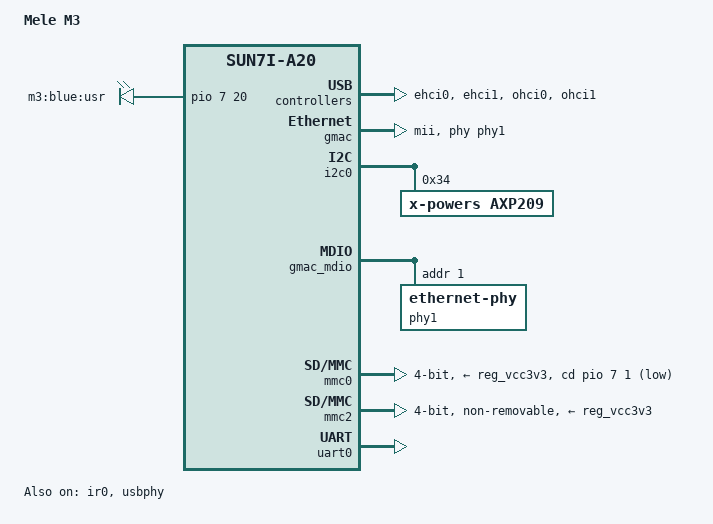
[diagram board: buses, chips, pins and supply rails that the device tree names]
/dts-v1/;
#include "sun7i-a20.dtsi"
#include "sunxi-common-regulators.dtsi"
#include <dt-bindings/gpio/gpio.h>
#include <dt-bindings/interrupt-controller/irq.h>
/ {
	model = "Mele M3";
	compatible = "mele,m3", "allwinner,sun7i-a20";
	aliases {
		serial0 = &uart0;
	};
	chosen {
		stdout-path = "serial0:115200n8";
	};
	leds {
		compatible = "gpio-leds";
		led {
			label = "m3:blue:usr";
			gpios = <&pio 7 20 GPIO_ACTIVE_HIGH>;
		};
	};
};
&ehci0 {
	status = "okay";
};
&ehci1 {
	status = "okay";
};
&gmac {
	pinctrl-names = "default";
	pinctrl-0 = <&gmac_mii_pins>;
	phy-handle = <&phy1>;
	phy-mode = "mii";
	status = "okay";
};
&i2c0 {
	status = "okay";
	axp209: pmic@34 {
		compatible = "x-powers,axp209";
		reg = <0x34>;
		interrupt-parent = <&nmi_intc>;
		interrupts = <0 IRQ_TYPE_LEVEL_LOW>;
		interrupt-controller;
		#interrupt-cells = <1>;
	};
};
&ir0 {
	pinctrl-names = "default";
	pinctrl-0 = <&ir0_rx_pin>;
	status = "okay";
};
&gmac_mdio {
	phy1: ethernet-phy@1 {
		reg = <1>;
	};
};
&mmc0 {
	vmmc-supply = <&reg_vcc3v3>;
	bus-width = <4>;
	cd-gpios = <&pio 7 1 GPIO_ACTIVE_LOW>;  
	status = "okay";
};
&mmc2 {
	vmmc-supply = <&reg_vcc3v3>;
	bus-width = <4>;
	non-removable;
	status = "okay";
};
&ohci0 {
	status = "okay";
};
&ohci1 {
	status = "okay";
};
&reg_usb1_vbus {
	status = "okay";
};
&reg_usb2_vbus {
	status = "okay";
};
&uart0 {
	pinctrl-names = "default";
	pinctrl-0 = <&uart0_pb_pins>;
	status = "okay";
};
&usbphy {
	usb1_vbus-supply = <&reg_usb1_vbus>;
	usb2_vbus-supply = <&reg_usb2_vbus>;
	status = "okay";
};
